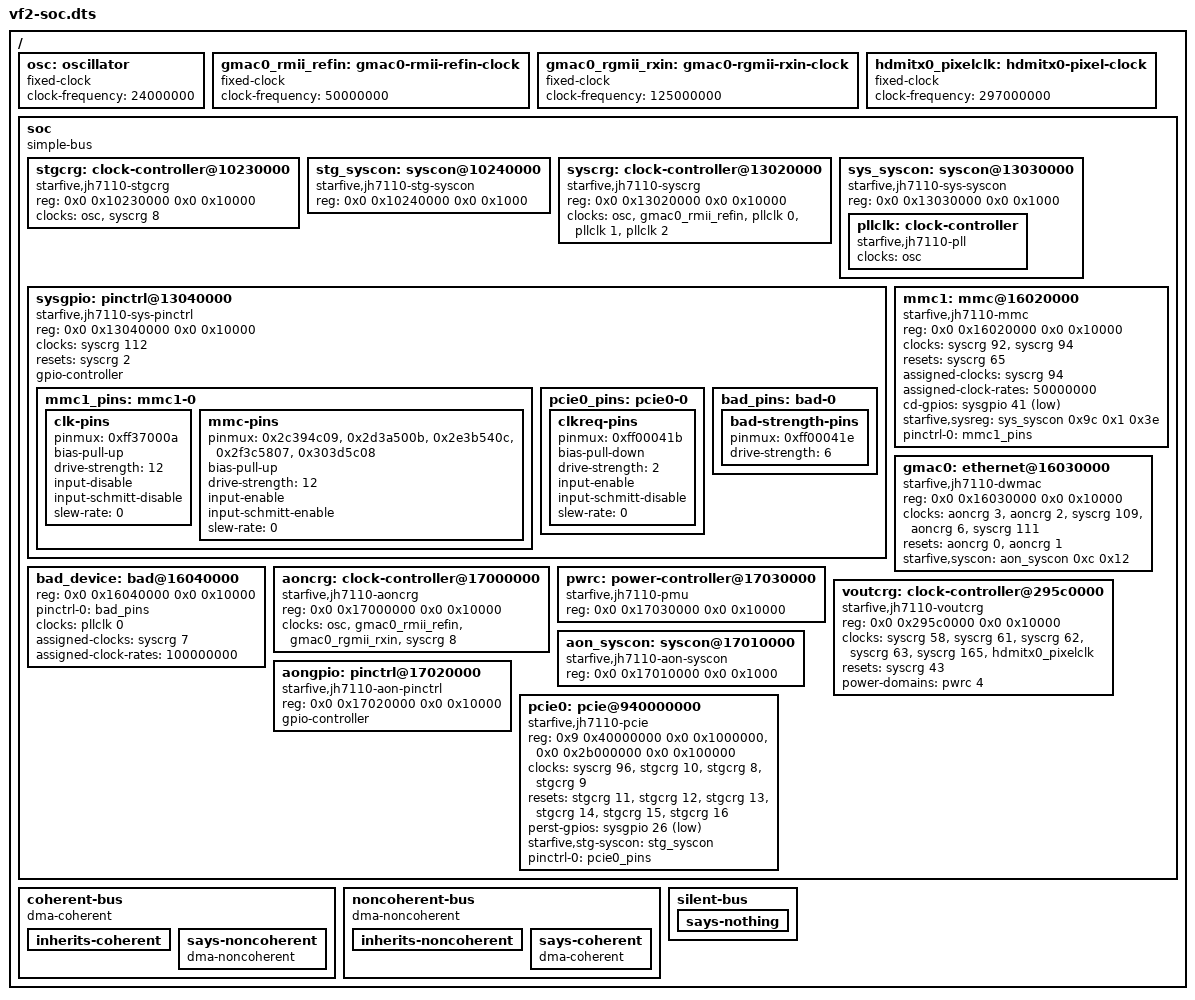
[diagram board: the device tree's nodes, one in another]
/*
 * A device tree in the shape of the VisionFive 2's (Linux v6.12
 * jh7110.dtsi and jh7110-common.dtsi): the clock generators, system
 * control blocks, pin controllers, the SD slot's controller, the first
 * Ethernet controller, the first PCIe host, the display's VOUT clock
 * generator and the power management unit, plus nodes for the DMA
 * coherency lookup.  GPIOMUX numbers are written out:
 * din << 24 | dout << 16 | doen << 10 | pin.
 */
/dts-v1/;

/ {
	#address-cells = <2>;
	#size-cells = <2>;

	osc: oscillator {
		compatible = "fixed-clock";
		#clock-cells = <0>;
		clock-frequency = <24000000>;
	};

	gmac0_rmii_refin: gmac0-rmii-refin-clock {
		compatible = "fixed-clock";
		#clock-cells = <0>;
		clock-frequency = <50000000>;
	};

	gmac0_rgmii_rxin: gmac0-rgmii-rxin-clock {
		compatible = "fixed-clock";
		#clock-cells = <0>;
		clock-frequency = <125000000>;
	};

	hdmitx0_pixelclk: hdmitx0-pixel-clock {
		compatible = "fixed-clock";
		#clock-cells = <0>;
		clock-frequency = <297000000>;
	};

	soc {
		compatible = "simple-bus";
		#address-cells = <2>;
		#size-cells = <2>;
		ranges;

		stgcrg: clock-controller@10230000 {
			compatible = "starfive,jh7110-stgcrg";
			reg = <0x0 0x10230000 0x0 0x10000>;
			clocks = <&osc>, <&syscrg 8>;
			clock-names = "osc", "stg_axiahb";
			#clock-cells = <1>;
			#reset-cells = <1>;
		};

		stg_syscon: syscon@10240000 {
			compatible = "starfive,jh7110-stg-syscon", "syscon";
			reg = <0x0 0x10240000 0x0 0x1000>;
		};

		syscrg: clock-controller@13020000 {
			compatible = "starfive,jh7110-syscrg";
			reg = <0x0 0x13020000 0x0 0x10000>;
			clocks = <&osc>, <&gmac0_rmii_refin>, <&pllclk 0>, <&pllclk 1>, <&pllclk 2>;
			clock-names = "osc", "gmac1_rmii_refin", "pll0_out", "pll1_out", "pll2_out";
			#clock-cells = <1>;
			#reset-cells = <1>;
		};

		sys_syscon: syscon@13030000 {
			compatible = "starfive,jh7110-sys-syscon", "syscon", "simple-mfd";
			reg = <0x0 0x13030000 0x0 0x1000>;

			pllclk: clock-controller {
				compatible = "starfive,jh7110-pll";
				clocks = <&osc>;
				#clock-cells = <1>;
			};
		};

		sysgpio: pinctrl@13040000 {
			compatible = "starfive,jh7110-sys-pinctrl";
			reg = <0x0 0x13040000 0x0 0x10000>;
			clocks = <&syscrg 112>;
			resets = <&syscrg 2>;
			gpio-controller;
			#gpio-cells = <2>;

			mmc1_pins: mmc1-0 {
				clk-pins {
					pinmux = <0xff37000a>;
					bias-pull-up;
					drive-strength = <12>;
					input-disable;
					input-schmitt-disable;
					slew-rate = <0>;
				};

				mmc-pins {
					pinmux = <0x2c394c09>, <0x2d3a500b>, <0x2e3b540c>,
						 <0x2f3c5807>, <0x303d5c08>;
					bias-pull-up;
					drive-strength = <12>;
					input-enable;
					input-schmitt-enable;
					slew-rate = <0>;
				};
			};

			pcie0_pins: pcie0-0 {
				clkreq-pins {
					pinmux = <0xff00041b>;
					bias-pull-down;
					drive-strength = <2>;
					input-enable;
					input-schmitt-disable;
					slew-rate = <0>;
				};
			};

			bad_pins: bad-0 {
				bad-strength-pins {
					pinmux = <0xff00041e>;
					drive-strength = <6>;
				};
			};
		};

		mmc1: mmc@16020000 {
			compatible = "starfive,jh7110-mmc";
			reg = <0x0 0x16020000 0x0 0x10000>;
			clocks = <&syscrg 92>, <&syscrg 94>;
			clock-names = "biu", "ciu";
			resets = <&syscrg 65>;
			reset-names = "reset";
			assigned-clocks = <&syscrg 94>;
			assigned-clock-rates = <50000000>;
			cd-gpios = <&sysgpio 41 1>;
			starfive,sysreg = <&sys_syscon 0x9c 0x1 0x3e>;
			pinctrl-names = "default";
			pinctrl-0 = <&mmc1_pins>;
		};

		gmac0: ethernet@16030000 {
			compatible = "starfive,jh7110-dwmac", "snps,dwmac-5.20";
			reg = <0x0 0x16030000 0x0 0x10000>;
			clocks = <&aoncrg 3>, <&aoncrg 2>, <&syscrg 109>, <&aoncrg 6>, <&syscrg 111>;
			clock-names = "stmmaceth", "pclk", "ptp_ref", "tx", "gtx";
			resets = <&aoncrg 0>, <&aoncrg 1>;
			reset-names = "stmmaceth", "ahb";
			starfive,syscon = <&aon_syscon 0xc 0x12>;
		};

		bad_device: bad@16040000 {
			reg = <0x0 0x16040000 0x0 0x10000>;
			pinctrl-0 = <&bad_pins>;
			clocks = <&pllclk 0>;
			assigned-clocks = <&syscrg 7>;
			assigned-clock-rates = <100000000>;
		};

		aoncrg: clock-controller@17000000 {
			compatible = "starfive,jh7110-aoncrg";
			reg = <0x0 0x17000000 0x0 0x10000>;
			clocks = <&osc>, <&gmac0_rmii_refin>, <&gmac0_rgmii_rxin>, <&syscrg 8>;
			clock-names = "osc", "gmac0_rmii_refin", "gmac0_rgmii_rxin", "stg_axiahb";
			#clock-cells = <1>;
			#reset-cells = <1>;
		};

		pwrc: power-controller@17030000 {
			compatible = "starfive,jh7110-pmu";
			reg = <0x0 0x17030000 0x0 0x10000>;
			#power-domain-cells = <1>;
		};

		voutcrg: clock-controller@295c0000 {
			compatible = "starfive,jh7110-voutcrg";
			reg = <0x0 0x295c0000 0x0 0x10000>;
			clocks = <&syscrg 58>, <&syscrg 61>, <&syscrg 62>, <&syscrg 63>,
				 <&syscrg 165>, <&hdmitx0_pixelclk>;
			clock-names = "vout_src", "vout_top_ahb", "vout_top_axi",
				      "vout_top_hdmitx0_mclk", "i2stx0_bclk", "hdmitx0_pixelclk";
			resets = <&syscrg 43>;
			#clock-cells = <1>;
			#reset-cells = <1>;
			power-domains = <&pwrc 4>;
		};

		aon_syscon: syscon@17010000 {
			compatible = "starfive,jh7110-aon-syscon", "syscon";
			reg = <0x0 0x17010000 0x0 0x1000>;
		};

		aongpio: pinctrl@17020000 {
			compatible = "starfive,jh7110-aon-pinctrl";
			reg = <0x0 0x17020000 0x0 0x10000>;
			gpio-controller;
			#gpio-cells = <2>;
		};

		pcie0: pcie@940000000 {
			compatible = "starfive,jh7110-pcie";
			reg = <0x9 0x40000000 0x0 0x1000000>, <0x0 0x2b000000 0x0 0x100000>;
			clocks = <&syscrg 96>, <&stgcrg 10>, <&stgcrg 8>, <&stgcrg 9>;
			clock-names = "noc", "tl", "axi_mst0", "apb";
			resets = <&stgcrg 11>, <&stgcrg 12>, <&stgcrg 13>, <&stgcrg 14>,
				 <&stgcrg 15>, <&stgcrg 16>;
			reset-names = "mst0", "slv0", "slv", "brg", "core", "apb";
			perst-gpios = <&sysgpio 26 1>;
			starfive,stg-syscon = <&stg_syscon>;
			pinctrl-0 = <&pcie0_pins>;
		};
	};

	coherent-bus {
		dma-coherent;

		inherits-coherent {
		};

		says-noncoherent {
			dma-noncoherent;
		};
	};

	noncoherent-bus {
		dma-noncoherent;

		inherits-noncoherent {
		};

		says-coherent {
			dma-coherent;
		};
	};

	silent-bus {
		says-nothing {
		};
	};
};
